VERSION ""

NS_ :

BS_:

BU_:

BO_ 84 EPRI_MCU_Cmd2_Response_0054: 5 Vector__XXX
 SG_ GENE_RotSpd : 0|16@1+ (1,-32767) [-32767|32768] "rpm" Vector__XXX
 SG_ GENE_EmergcyStp_flg : 35|1@1+ (1,0) [0|1] "" Vector__XXX

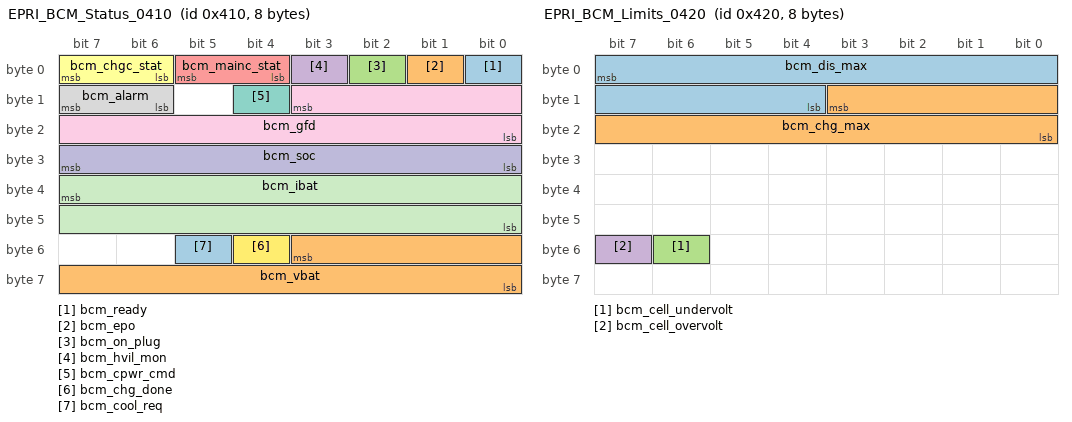
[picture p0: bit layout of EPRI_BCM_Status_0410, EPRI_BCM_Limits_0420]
BO_ 1040 EPRI_BCM_Status_0410: 8 Vector__XXX
 SG_ bcm_ready : 0|1@1+ (1,0) [0|1] "" Vector__XXX
 SG_ bcm_epo : 1|1@1+ (1,0) [0|1] "" Vector__XXX
 SG_ bcm_on_plug : 2|1@1+ (1,0) [0|1] "" Vector__XXX
 SG_ bcm_hvil_mon : 3|1@1+ (1,0) [0|1] "" Vector__XXX
 SG_ bcm_mainc_stat : 4|2@1+ (1,0) [0|3] "" Vector__XXX
 SG_ bcm_chgc_stat : 6|2@1+ (1,0) [0|3] "" Vector__XXX
 SG_ bcm_cpwr_cmd : 12|1@1+ (1,0) [0|1] "" Vector__XXX
 SG_ bcm_alarm : 14|2@1+ (1,0) [0|3] "" Vector__XXX
 SG_ bcm_gfd : 11|12@0+ (0.25,0) [0|1023.75] "" Vector__XXX
 SG_ bcm_soc : 24|8@1+ (0.5,0) [0|127.5] "%" Vector__XXX
 SG_ bcm_ibat : 39|16@0+ (0.025,-1000) [-1000|639.175] "A" Vector__XXX
 SG_ bcm_chg_done : 52|1@1+ (1,0) [0|1] "" Vector__XXX
 SG_ bcm_cool_req : 53|1@1+ (1,0) [0|1] "" Vector__XXX
 SG_ bcm_vbat : 51|12@0+ (0.25,0) [0|1023.75] "V" Vector__XXX

BO_ 1056 EPRI_BCM_Limits_0420: 8 Vector__XXX
 SG_ bcm_dis_max : 7|12@0+ (0.25,0) [0|1023.75] "A" Vector__XXX
 SG_ bcm_chg_max : 11|12@0+ (0.25,0) [0|1023.75] "A" Vector__XXX
 SG_ bcm_cell_undervolt : 54|1@1+ (1,0) [0|1] "" Vector__XXX
 SG_ bcm_cell_overvolt : 55|1@1+ (1,0) [0|1] "" Vector__XXX

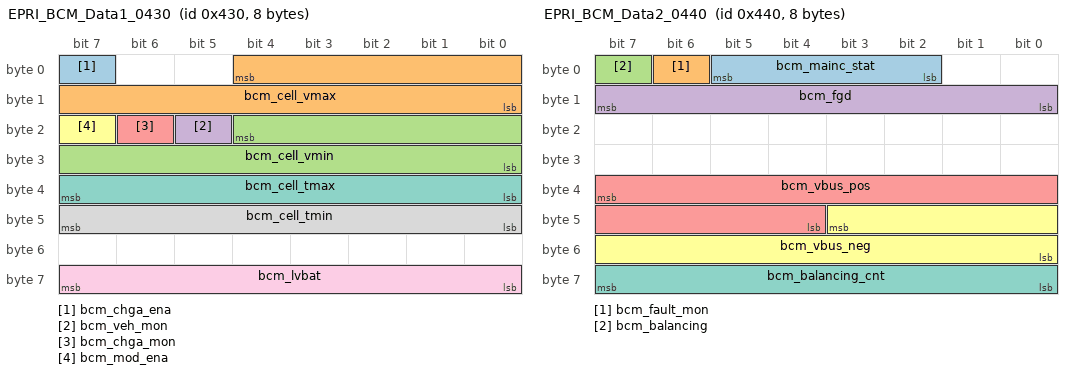
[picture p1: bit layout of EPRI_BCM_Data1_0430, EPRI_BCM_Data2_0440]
BO_ 1072 EPRI_BCM_Data1_0430: 8 Vector__XXX
 SG_ bcm_chga_ena : 7|1@1+ (1,0) [0|1] "" Vector__XXX
 SG_ bcm_cell_vmax : 4|13@0+ (0.001,0) [0|3.8] "V" Vector__XXX
 SG_ bcm_cell_vmin : 20|13@0+ (0.001,0) [0|3.8] "V" Vector__XXX
 SG_ bcm_veh_mon : 21|1@1+ (1,0) [0|1] "" Vector__XXX
 SG_ bcm_chga_mon : 22|1@1+ (1,0) [0|1] "" Vector__XXX
 SG_ bcm_mod_ena : 23|1@1+ (1,0) [0|1] "" Vector__XXX
 SG_ bcm_cell_tmax : 32|8@1+ (0.5,-40) [-40|80] "degC" Vector__XXX
 SG_ bcm_cell_tmin : 40|8@1+ (0.5,-40) [-40|80] "degC" Vector__XXX
 SG_ bcm_lvbat : 56|8@1+ (0.1,0) [0|25.3] "V" Vector__XXX

BO_ 1088 EPRI_BCM_Data2_0440: 8 Vector__XXX
 SG_ bcm_mainc_stat : 2|4@1+ (1,0) [0|15] "" Vector__XXX
 SG_ bcm_fault_mon : 6|1@1+ (1,0) [0|1] "" Vector__XXX
 SG_ bcm_balancing : 7|1@1+ (1,0) [0|1] "" Vector__XXX
 SG_ bcm_fgd : 8|8@1+ (0.5,0) [0|126.5] "%" Vector__XXX
 SG_ bcm_vbus_pos : 39|12@0+ (0.25,0) [0|1023.75] "V" Vector__XXX
 SG_ bcm_vbus_neg : 43|12@0+ (0.25,-500) [-500|523.75] "V" Vector__XXX
 SG_ bcm_balancing_cnt : 56|8@1+ (1,0) [0|253] "" Vector__XXX

BO_ 1137 EPRI_MCU_Info2_0471: 7 Vector__XXX
 SG_ GENE_Mot_Trq : 0|16@1+ (0.125,-4096) [-4096|4095.875] "Nm" Vector__XXX

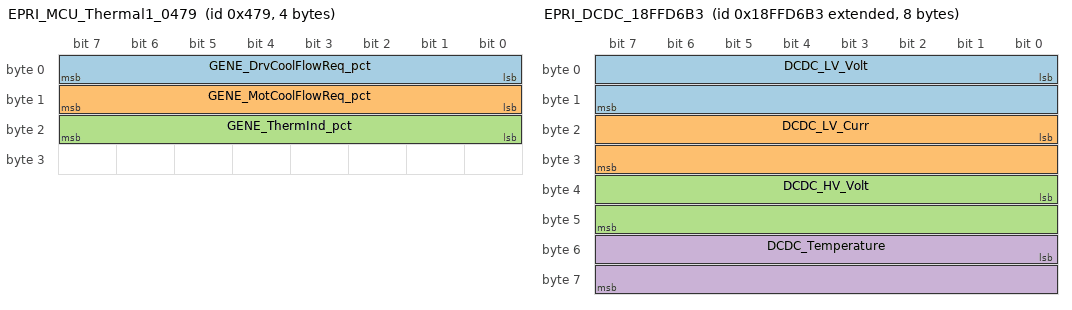
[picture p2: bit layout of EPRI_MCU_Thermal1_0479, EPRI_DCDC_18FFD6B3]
BO_ 1145 EPRI_MCU_Thermal1_0479: 4 Vector__XXX
 SG_ GENE_DrvCoolFlowReq_pct : 0|8@1+ (0.78125,0) [0|100] "%" Vector__XXX
 SG_ GENE_MotCoolFlowReq_pct : 8|8@1+ (0.78125,0) [0|100] "%" Vector__XXX
 SG_ GENE_ThermInd_pct : 16|8@1+ (0.78125,0) [0|100] "%" Vector__XXX

BO_ 2566903475 EPRI_DCDC_18FFD6B3: 8 Vector__XXX
 SG_ DCDC_LV_Volt : 0|16@1+ (0.05,0) [0|3276.75] "V" Vector__XXX
 SG_ DCDC_LV_Curr : 16|16@1+ (0.05,0) [0|3276.75] "A" Vector__XXX
 SG_ DCDC_HV_Volt : 32|16@1+ (0.05,0) [0|3276.75] "V" Vector__XXX
 SG_ DCDC_Temperature : 48|16@1- (0.1,0) [-3276.8|3276.7] "degC" Vector__XXX

BO_ 1609 VCM_EvapControl_0649: 8 VCM
 SG_ vcm_evap_active : 39|1@1+ (1,0) [0|1] "" Vector__XXX
 SG_ vcm_evap_counter : 19|12@0+ (1,0) [0|4095] "" Vector__XXX

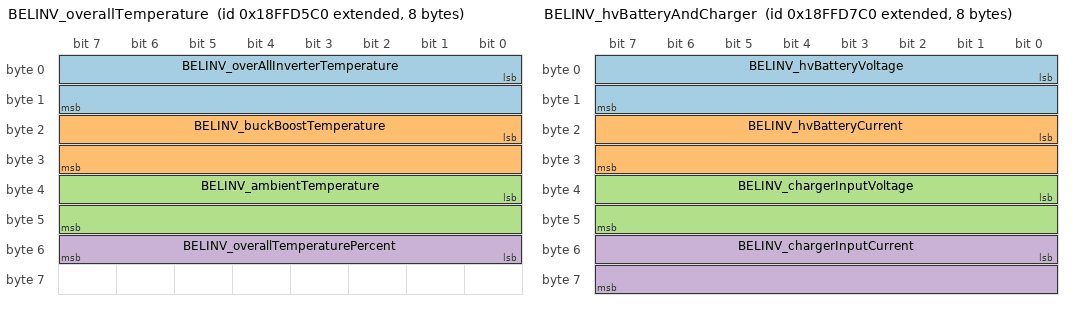
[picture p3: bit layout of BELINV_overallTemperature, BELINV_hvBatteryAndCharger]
BO_ 2566903232 BELINV_overallTemperature: 8 BELINV
 SG_ BELINV_overAllInverterTemperature : 0|16@1- (0.1,0) [-32768|32767] "" Vector__XXX
 SG_ BELINV_buckBoostTemperature : 16|16@1- (0.1,0) [-32768|32767] "" Vector__XXX
 SG_ BELINV_ambientTemperature : 32|16@1- (0.1,0) [-32768|32767] "" Vector__XXX
 SG_ BELINV_overallTemperaturePercent : 48|8@1+ (1,0) [0|100] "%" Vector__XXX

BO_ 2566903744 BELINV_hvBatteryAndCharger: 8 BELINV
 SG_ BELINV_hvBatteryVoltage : 0|16@1+ (0.05,0) [0|65535] "" Vector__XXX
 SG_ BELINV_hvBatteryCurrent : 16|16@1- (0.05,0) [-32768|32767] "" Vector__XXX
 SG_ BELINV_chargerInputVoltage : 32|16@1+ (0.05,0) [0|65535] "" Vector__XXX
 SG_ BELINV_chargerInputCurrent : 48|16@1+ (0.05,0) [0|65535] "" Vector__XXX

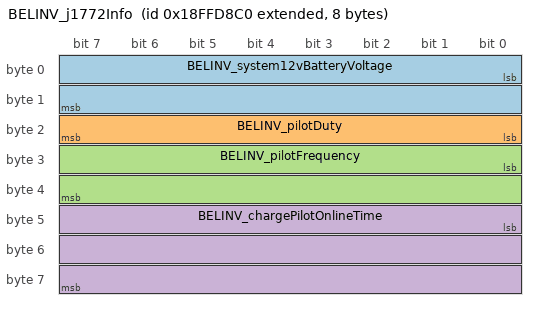
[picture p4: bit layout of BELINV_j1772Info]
BO_ 2566904000 BELINV_j1772Info: 8 BELINV
 SG_ BELINV_system12vBatteryVoltage : 0|16@1+ (0.02,0) [0|65535] "" Vector__XXX
 SG_ BELINV_pilotDuty : 16|8@1+ (1,0) [0|255] "" Vector__XXX
 SG_ BELINV_pilotFrequency : 24|16@1+ (1,0) [0|65535] "" Vector__XXX
 SG_ BELINV_chargePilotOnlineTime : 40|24@1+ (1,0) [0|16777216] "" Vector__XXX

BO_ 2566904256 BELINV_chargeInfo: 8 BELINV
 SG_ BELINV_maxAvailableChargingCurrent : 0|16@1- (0.05,0) [-32768|32767] "" Vector__XXX
 SG_ BELINV_vehicleState : 16|8@1+ (1,0) [0|255] "" Vector__XXX

CM_ BO_ 84 "Via Motors GENE (generator) MCU.";
CM_ SG_ 84 GENE_RotSpd "Zero at raw=32767 (0x7FFF). Note: GENE uses 32767, not 32768 like trac_rpm.";
CM_ BO_ 1040 "A123 BMS status message. bcm_mainc_stat and bcm_chgc_stat share the OPEN/CLOSED/HIGH/LOW array. bcm_alarm is a 4-entry NONE/TYPE1/TYPE2/TYPE3 array from B1[7:6].";
CM_ SG_ 1040 bcm_gfd "Ground fault detection (isolation monitor). Normal=1000.0 (raw=4000). Fault=0.0 (raw=0) -- fires 150ms before EPO in isolation test; does not fire in charge fault EPO or normal drives.";
CM_ SG_ 1040 bcm_ibat "Negative=discharge, positive=charge. Zero at raw=40000. Invalid if (raw & 0xFFFE)==0xFFFE.";
CM_ SG_ 1040 bcm_mainc_stat "Shares array with bcm_chgc_stat.";
CM_ SG_ 1040 bcm_chgc_stat "Shares array with bcm_mainc_stat.";
VAL_ 1040 bcm_alarm 0 "NONE" 1 "TYPE1" 2 "TYPE2" 3 "TYPE3" ;
VAL_ 1040 bcm_chgc_stat 0 "OPEN" 1 "CLOSED" 2 "HIGH" 3 "LOW" ;
VAL_ 1040 bcm_mainc_stat 0 "OPEN" 1 "CLOSED" 2 "HIGH" 3 "LOW" ;
CM_ BO_ 1056 "A123 BMS charge/discharge current limits. bcm_cell_overvolt/undervolt are boolean flags from B6.";
CM_ BO_ 1072 "A123 BMS cell data. Voltage sentinel 0x1FFE (8.190V) falls inside declared range -- EPRI uses explicit equality checks, not range filtering. Temperature sentinel raw>=0xFE excluded by DBC range. bcm_lvbat B7[6:5]=0x60 when 12V falls below 12.8V (BMS offline) -- BMS_ValidityMux byproduct, not a dedicated flag.";
CM_ SG_ 1072 bcm_cell_vmax "Sentinel raw=0x1FFE (8.190V) excluded by DBC range -- healthy LFP cells stay below 3.8V.";
CM_ SG_ 1072 bcm_cell_tmax "Sentinel raw>=0xFE excluded by DBC range. Supersedes prior experimental formula raw-100.";
CM_ SG_ 1072 bcm_lvbat "Typical: 14.0V (DCDC running), 12.7V (at rest/shutdown).";
CM_ BO_ 1088 "A123 BMS balancing state and HV bus voltages. bcm_mainc_stat here is 4-bit (16-entry contactor state machine) -- distinct from 2-bit bcm_mainc_stat in 0x0410.";
CM_ SG_ 1088 bcm_mainc_stat "16-entry contactor sequence state machine. See VAL_.";
CM_ SG_ 1088 bcm_fgd "Role unconfirmed (plist label only). Always at sentinel 0xFE in all 73 captured logs -- never populated by this BMS configuration.";
CM_ SG_ 1088 bcm_vbus_neg "Zero at raw=2000.";
VAL_ 1088 bcm_mainc_stat 0 "ALL_OPEN" 1 "FAILED_MAINP_OR_R_WELD" 2 "CLOSE_MAINR" 3 "FAILED_MAINR_OPEN" 4 "FAILED_MAINN_WELD" 5 "CLOSE_MAINN" 6 "FAILED_MAINN_OPEN" 7 "WAIT_PRECHARGE" 8 "CLOSE_MAINP" 9 "OPEN_MAINR" 10 "FAILED_MAINP_OPEN" 11 "MAIN_PN_CLOSED_DRIVE" 12 "MAIN_P_CLOSED_CHARGE" 13 "SHUTDOWN_REQUEST" 14 "ALL_OPEN_SHUTDOWN" ;
CM_ BO_ 1137 "Via Motors GENE MCU motor torque. B2-B6 uncharacterized.";
CM_ SG_ 1137 GENE_Mot_Trq "Zero at raw=32768. Offset -4096 Nm.";
CM_ BO_ 1145 "Via Motors GENE MCU thermal status.";
CM_ BO_ 1145 "B3 uncharacterized.";
CM_ BO_ 2566903475 "Separate DC-DC step-down converter (NOT the Bel INVCH unit). Not in BelInverter.dbc.";
CM_ BO_ 1609 "VCU/VCM evap canister purge control. 0x649 on PT bus, ~20 Hz, VCU-sourced. Full message encoding differs between drive and charge modes -- byte fields repurpose themselves; values cannot be compared across modes. B0 role UNRESOLVED: it was previously mapped as the evap-active flag (bit 7) and that mapping is now invalidated -- see notes/evap-cycle-analysis.md Phase 5. B1 role unresolved. B2 upper nibble is a free-running clock independent of evap state.";
CM_ SG_ 1609 vcm_evap_active "B4 bit 7. 1 = evap cycle pending or purging; 0 = not pending. Set at key-on when a cycle is due, before the engine ever runs, and clears at VCM-declared completion (~6.1s before the generator is commanded to stop). Holds through involuntary stalls -- tracks VCM intent, not engine state. Verified across all 104 logged sessions containing 0x649: set in 17/17 sessions where a purge actually ran, never set spuriously. NOTE: this flag alone does not distinguish PENDING from PURGING -- pair it with vcm_evap_counter (0 = pending, >0 = purging).";
CM_ SG_ 1609 vcm_evap_counter "12-bit purge progress counter: B2 lower nibble = MSB, B3 = LSB. 0 whenever no cycle is active. Counts up only while the engine is running during an active evap cycle; frozen when the engine stops (stall or controlled off) and resumes on restart; survives log gaps and key cycles within a cycle. Returns to 0 at completion. Rate is variable (~0.1-1.0 counts/s, ramps up then down) and the terminal value differs per cycle (observed 901, 901, 856), so this is NOT a percentage and cannot drive a progress bar. Use only as a zero/non-zero purging discriminator.";
CM_ BO_ 2566903232 "(SA=0xC0). Bel inverter/charger temperatures. EPRI app: INVCH_Bdc_Temp. B0:B3 from previous DBC only. Note: EPRI identifies B4:B5 as BDC internal temperature, not ambient. overallTemperaturePercent corrected to 8-bit (B6 only); previous DBC had 16-bit.";
CM_ BO_ 2566903744 "(SA=0xC0). Bel charger HV battery and AC input. EPRI app: INVCH_Bdc_Ibat. hvBatteryCurrent is signed (bidirectional); other signals unsigned (corrected from previous DBC). SIGN CORRECTION 2026-08-03: the value is NEGATIVE while the pack is charging -- the previously documented positive=charging convention is WRONG. Verified across 16 charge sessions: negating gives |E_dc|/E_ac = 90-93% (a sane charger efficiency) and agrees with BMS pack energy from 0x410. chargerInputVoltage/Current are RMS, so V*I is APPARENT power (VA) not real power; at light load PF degrades and efficiency computed from them is a lower bound. See notes/charger-efficiency-and-grid-consumption.md.";
CM_ BO_ 2566904000 "(SA=0xC0). Bel J1772 pilot and 12V monitoring. EPRI app: INVCH_Bdc_12Vbat. B2-B7 from previous DBC only.";
CM_ BO_ 2566904256 "(SA=0xC0). Bel available charge current and vehicle state. Source: previous DBC. Not in EPRI plist.";
CM_ SG_ 2566904256 BELINV_maxAvailableChargingCurrent "DC/pack-side charge current limit, NOT the J1772 AC advertised current. Tracks HV battery current (~13 A limit vs -12.4 A actual during a 5 kW charge). The J1772 advertised current is not on CAN -- derive it from BELINV_pilotDuty per SAE J1772. Confirmed 2026-07-14, live charge log. See android-app/notes/plans/vtrux-live-display.md.";
